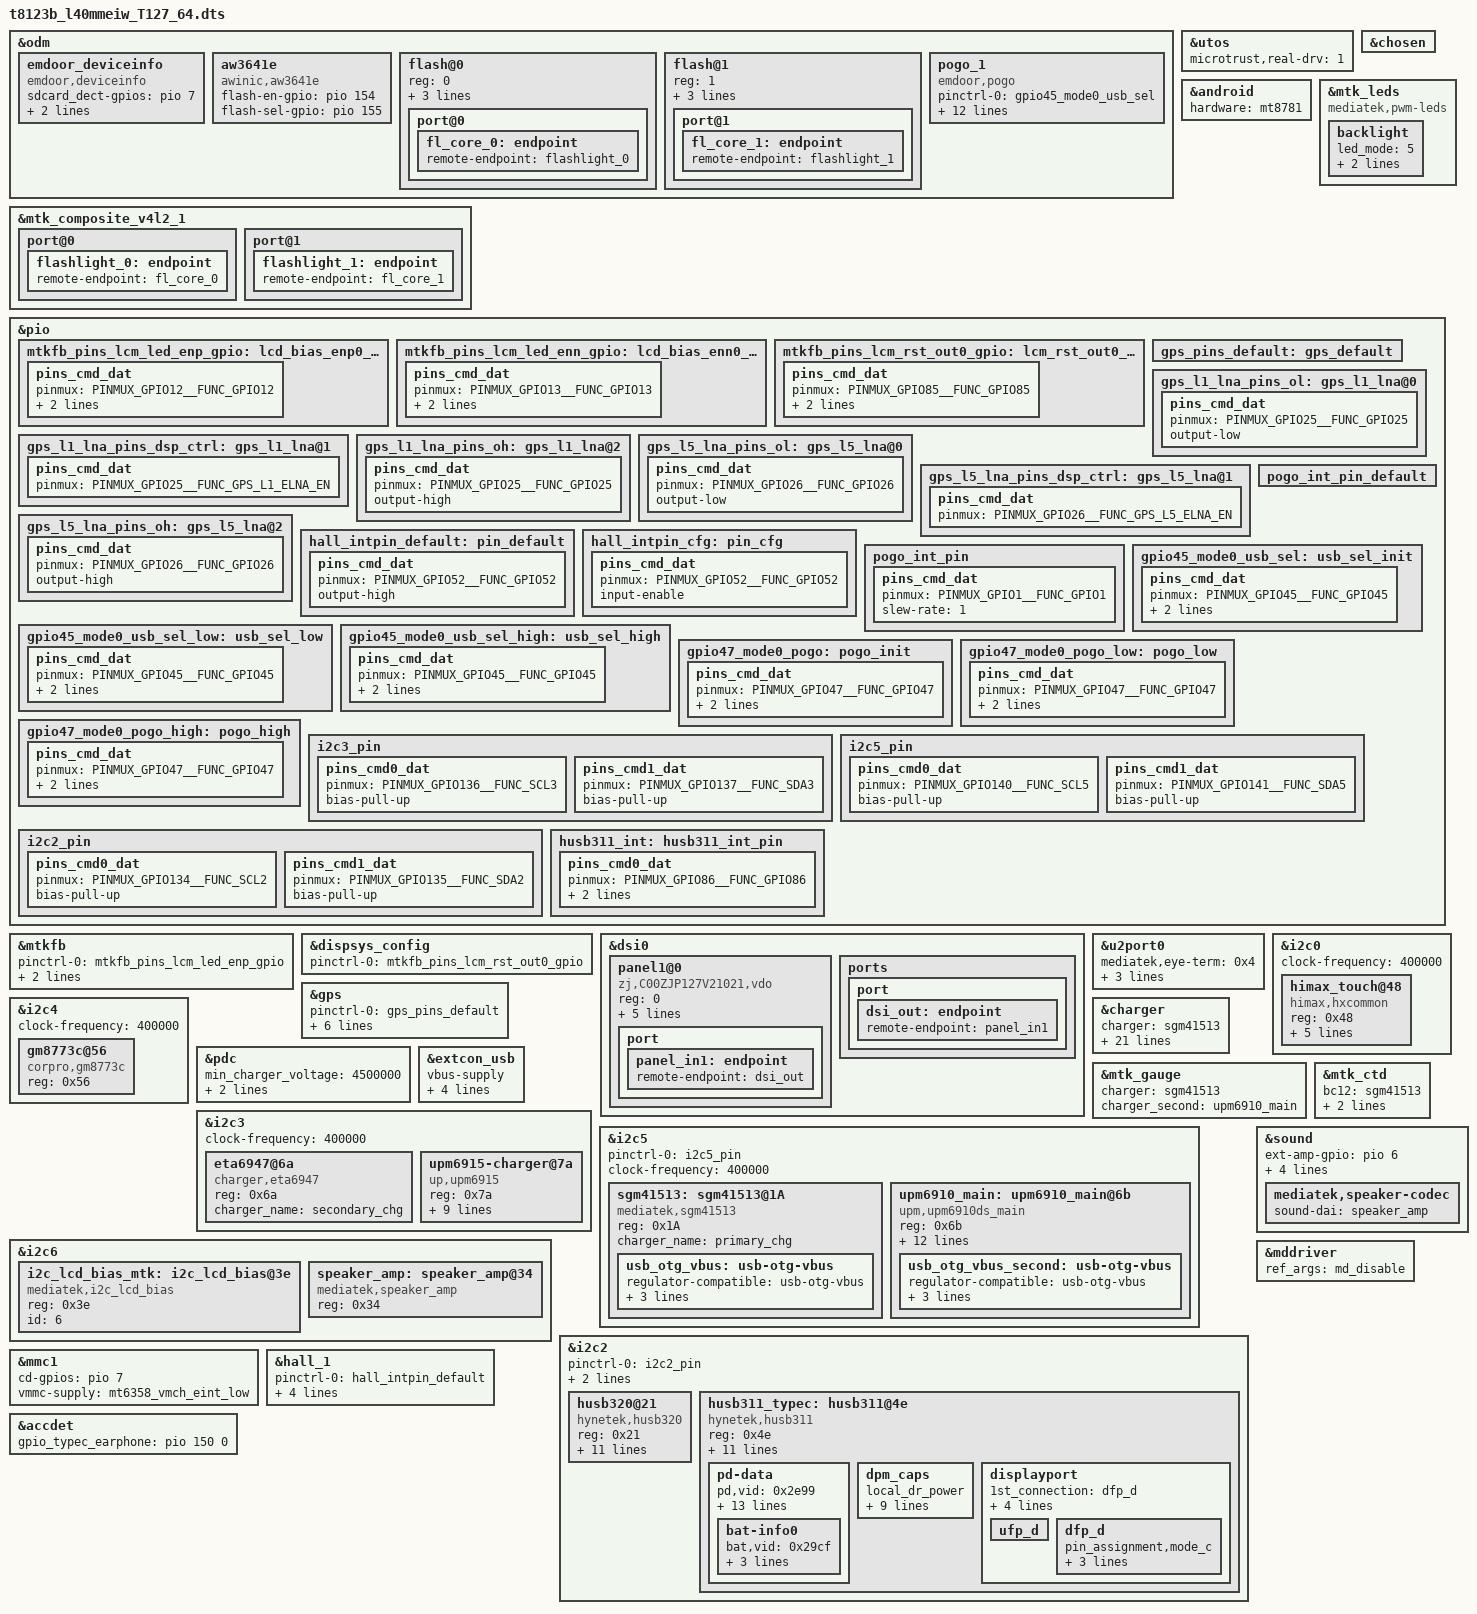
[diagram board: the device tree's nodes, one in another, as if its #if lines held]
// SPDX-License-Identifier: (GPL-2.0 OR MIT)
/*
 * Copyright (C) 2021 MediaTek Inc.
 */
/dts-v1/;
/plugin/;
#include <dt-bindings/interrupt-controller/arm-gic.h>
#include <dt-bindings/interrupt-controller/irq.h>
#include <dt-bindings/pinctrl/mt6789-pinfunc.h>
#include <dt-bindings/gpio/gpio.h>
#include "mediatek/cust_t8123b_l40mmeiw_T1095_64_camera.dtsi"

&odm {
	emdoor_deviceinfo:emdoor_deviceinfo{
		compatible = "emdoor,deviceinfo";
		sdcard_dect-gpios = <&pio 7 0>;
		ddr-name =
			"RS2G32LX4D8BNR_53BT_CX",
			"RS1G32LV4D2BDS_53BT_CX";
		status = "okay";
	};

	/* aw3641e flash  */
	aw3641e:aw3641e {
		compatible = "awinic,aw3641e";
		flash-en-gpio = <&pio 154 0>;
		flash-sel-gpio = <&pio 155 0>;
		status = "okay";
	};
	flash@0{
		reg = <0>;
		type = <0>;
		ct = <0>;
		part = <0>;
		port@0 {
			fl_core_0: endpoint {
				remote-endpoint = <&flashlight_0>;
			};
		};
	};
	flash@1{
		reg = <1>;
		type = <0>;
		ct = <1>;
		part = <0>;
		port@1 {
			fl_core_1: endpoint {
				remote-endpoint = <&flashlight_1>;
			};
		};
	};
    pogo_1: pogo_1{
        compatible = "emdoor,pogo";
        status = "okay";
    };
};

&mtk_composite_v4l2_1 {
	port@0 {
		flashlight_0: endpoint {
			remote-endpoint = <&fl_core_0>;
		};
	};
	port@1 {
		flashlight_1: endpoint {
			remote-endpoint = <&fl_core_1>;
		};
	};
};
/* Microtrust(TEEI) utos real driver */
&utos{
       microtrust,real-drv = <1>;
};

&chosen {
};

&android {
	hardware = "mt8781";
};

&mtk_leds {
	compatible = "mediatek,pwm-leds";

	backlight {
		led_mode = <5>;
		pwms =  <&disp_pwm 0 39285>;
		pwm_config = <0 1 0 0 0>;
	};
};

&pio {
	mtkfb_pins_lcm_led_enp_gpio: lcd_bias_enp0_gpio {
		pins_cmd_dat {
			pinmux = <PINMUX_GPIO12__FUNC_GPIO12>;
			slew-rate = <1>;
			output-low;
		};
	};

	mtkfb_pins_lcm_led_enn_gpio: lcd_bias_enn0_gpio {
		pins_cmd_dat {
			pinmux = <PINMUX_GPIO13__FUNC_GPIO13>;
			slew-rate = <1>;
			output-low;
		};
	};

	mtkfb_pins_lcm_rst_out0_gpio: lcm_rst_out0_gpio {
		pins_cmd_dat {
			pinmux = <PINMUX_GPIO85__FUNC_GPIO85>;
			slew-rate = <1>;
			output-low;
		};
	};
};

&mtkfb {
	pinctrl-names = "lcd_bias_enp0_gpio", "lcd_bias_enn0_gpio", "lcm_rst_out0_gpio";
	pinctrl-0 = <&mtkfb_pins_lcm_led_enp_gpio>;
	pinctrl-1 = <&mtkfb_pins_lcm_led_enn_gpio>;
	pinctrl-2 = <&mtkfb_pins_lcm_rst_out0_gpio>;
	status = "okay";
};

&dispsys_config {
	pinctrl-names = "lcm_rst_out0_gpio";
	pinctrl-0 = <&mtkfb_pins_lcm_rst_out0_gpio>;
	status = "okay";
};

&dsi0 {
	status = "okay";
	#address-cells = <1>;
	#size-cells = <0>;
	panel1@0 {
		compatible = "zj,C00ZJP127V21021,vdo";
		reg = <0>;
		reset-gpios = <&pio 85 0>;
		vdd_en-gpios = <&pio 159 0>;
		ivdd12_en-gpios = <&pio 34 0>;
		ovdd18_en-gpios = <&pio 36 0>;
		bias-gpios = <&pio 12 0>, <&pio 13 0>;
		pinctrl-names = "default";
		port {
			panel_in1: endpoint {
				remote-endpoint = <&dsi_out>;
			};
		};
	};

	ports {
		port {
			dsi_out: endpoint {
				remote-endpoint = <&panel_in1>;
			};
		};
	};
};

&u2port0 {
		mediatek,eye-term = <0x4>;
		mediatek,eye-vrt = <0x5>;
		mediatek,rev6 = <3>;
		mediatek,discth = <0xf>;
};

/* GPS GPIO standardization start */
&pio {
	gps_pins_default: gps_default {
	};
	gps_l1_lna_pins_ol: gps_l1_lna@0 {
		pins_cmd_dat {
			pinmux = <PINMUX_GPIO25__FUNC_GPIO25>;
			output-low;
		};
	};
	gps_l1_lna_pins_dsp_ctrl: gps_l1_lna@1 {
		pins_cmd_dat {
			pinmux = <PINMUX_GPIO25__FUNC_GPS_L1_ELNA_EN>;
		};
	};
	gps_l1_lna_pins_oh: gps_l1_lna@2 {
		pins_cmd_dat {
			pinmux = <PINMUX_GPIO25__FUNC_GPIO25>;
			output-high;
		};
	};
	gps_l5_lna_pins_ol: gps_l5_lna@0 {
		pins_cmd_dat {
			pinmux = <PINMUX_GPIO26__FUNC_GPIO26>;
			output-low;
		};
	};
	gps_l5_lna_pins_dsp_ctrl: gps_l5_lna@1 {
		pins_cmd_dat {
			pinmux = <PINMUX_GPIO26__FUNC_GPS_L5_ELNA_EN>;
		};
	};
	gps_l5_lna_pins_oh: gps_l5_lna@2 {
		pins_cmd_dat {
			pinmux = <PINMUX_GPIO26__FUNC_GPIO26>;
			output-high;
		};
	};

	hall_intpin_default: pin_default {
		pins_cmd_dat {
			pinmux = <PINMUX_GPIO52__FUNC_GPIO52>;
			output-high;
		};
	};
	hall_intpin_cfg: pin_cfg {
		pins_cmd_dat {
			pinmux = <PINMUX_GPIO52__FUNC_GPIO52>;
			input-enable;
		};
	};
/**pogo start**/
    pogo_int_pin_default: pogo_int_pin_default {
    };

    pogo_int_pin: pogo_int_pin {
        pins_cmd_dat {
            pinmux = <PINMUX_GPIO1__FUNC_GPIO1>;
            slew-rate = <1>;
        };
    };

    gpio45_mode0_usb_sel: usb_sel_init {
        pins_cmd_dat {
            pinmux = <PINMUX_GPIO45__FUNC_GPIO45>;
            slew-rate = <0>;
            bias-disable;
        };
    };

    gpio45_mode0_usb_sel_low: usb_sel_low {
        pins_cmd_dat {
            pinmux = <PINMUX_GPIO45__FUNC_GPIO45>;
            slew-rate = <1>;
            output-low;
        };
    };

    gpio45_mode0_usb_sel_high: usb_sel_high {
        pins_cmd_dat {
                pinmux = <PINMUX_GPIO45__FUNC_GPIO45>;
                slew-rate = <1>;
                output-high;
        };
    };

    gpio47_mode0_pogo: pogo_init {
        pins_cmd_dat {
                pinmux = <PINMUX_GPIO47__FUNC_GPIO47>;
                slew-rate = <0>;
                bias-disable;
        };
    };

    gpio47_mode0_pogo_low: pogo_low {
        pins_cmd_dat {
                pinmux = <PINMUX_GPIO47__FUNC_GPIO47>;
                slew-rate = <1>;
                output-low;
        };
    };

    gpio47_mode0_pogo_high: pogo_high {
        pins_cmd_dat {
                pinmux = <PINMUX_GPIO47__FUNC_GPIO47>;
                slew-rate = <1>;
                output-high;
        };
    };
/**pogo end**/

	i2c3_pin: i2c3_pin {
		pins_cmd0_dat {
			pinmux = <PINMUX_GPIO136__FUNC_SCL3>;
			bias-pull-up;
		};
		pins_cmd1_dat {
			pinmux = <PINMUX_GPIO137__FUNC_SDA3>;
			bias-pull-up;
		};
	};


	i2c5_pin: i2c5_pin {
		pins_cmd0_dat {
			pinmux = <PINMUX_GPIO140__FUNC_SCL5>;
			bias-pull-up;
		};
		pins_cmd1_dat {
			pinmux = <PINMUX_GPIO141__FUNC_SDA5>;
			bias-pull-up;
		};
	};

	i2c2_pin: i2c2_pin {
		pins_cmd0_dat {
			pinmux = <PINMUX_GPIO134__FUNC_SCL2>;
			bias-pull-up;
		};
		pins_cmd1_dat {
			pinmux = <PINMUX_GPIO135__FUNC_SDA2>;
			bias-pull-up;
		};
	};

	husb311_int: husb311_int_pin {
		pins_cmd0_dat {
			pinmux = <PINMUX_GPIO86__FUNC_GPIO86>;
			bias-pull-up;
			input-enable;
		};
	};

};
&gps {
	pinctrl-names = "default",
		"gps_l1_lna_disable",
		"gps_l1_lna_dsp_ctrl",
		"gps_l1_lna_enable",
		"gps_l5_lna_disable",
		"gps_l5_lna_dsp_ctrl",
		"gps_l5_lna_enable";
	pinctrl-0 = <&gps_pins_default>;
	pinctrl-1 = <&gps_l1_lna_pins_ol>;
	pinctrl-2 = <&gps_l1_lna_pins_dsp_ctrl>;
	pinctrl-3 = <&gps_l1_lna_pins_oh>;
	pinctrl-4 = <&gps_l5_lna_pins_ol>;
	pinctrl-5 = <&gps_l5_lna_pins_dsp_ctrl>;
	pinctrl-6 = <&gps_l5_lna_pins_oh>;
	status = "okay";
};
/* GPS GPIO standardization end */

&i2c0 {
    status = "okay";
    clock-frequency = <400000>;
    himax_touch@48 {
        compatible = "himax,hxcommon";
        reg = <0x48>;
        interrupt-parent = <&pio>;
        himax,panel-coords= <0 1600 0 2176>;
        himax,display-coords= <0 1600 0 2176>;
        himax,irq-gpio = <&pio 9 0x2008>;
        himax,rst-gpio = <&pio 152 0x00>;
        status = "okay" ;
    };
};

&i2c4 {
    status = "okay";
    clock-frequency = <400000>;
    gm8773c@56 {
        compatible = "corpro,gm8773c";
        reg = <0x56>;
        status = "okay";
    };
};

&charger {
	charger = <&sgm41513>;
	charger_second = <&upm6910_main>;
	battery_cv_zl = <4400000>;
	battery_cv_ytl = <4350000>;
	/* charging current */
	usb_charger_current = <500000>;
	ac_charger_current = <3000000>;
	ac_charger_input_current = <2000000>;

	chg1_ac_charger_current = <3000000>;
	chg1_ac_charger_input_current = <1100000>;

	chg2_ac_charger_current = <3000000>;
	chg2_ac_charger_input_current = <1000000>;

	charging_host_charger_current = <1500000>;

	max_charger_voltage = <12000000>;
	min_charge_temp = <0>;
	min_charge_temp_plus_x_degree = <2>;
	max_charge_temp = <45>;
	max_charge_temp_minus_x_degree = <42>;
	charger_configuration= <1>;
	/* dynamic mivr */
	enable_dynamic_mivr;
	min_charger_voltage_1 = <4600000>;
	min_charger_voltage_2 = <4600000>;
	max_dmivr_charger_current = <1800000>;
};

&pdc {
		min_charger_voltage = <4500000>;
		pd_vbus_low_bound = <5000000>;
		pd_vbus_upper_bound = <9000000>;
};

&mtk_gauge {
	charger = <&sgm41513>;
	charger_second = <&upm6910_main>;
};

&extcon_usb {
	status= "okay";
	vbus-supply;
	vbus-voltage;
	vbus-current;
	charger = <&sgm41513>;
	charger_second = <&upm6910_main>;
};

&mtk_ctd {
	bc12 = <&sgm41513>;
	bc12_second = <&upm6910_main>;
	bc12_sel = <0>;
};

&i2c3 {
	status = "okay";
	clock-frequency = <400000>;
	eta6947@6a {
		compatible = "charger,eta6947";
		reg = <0x6a>;
		charger_name = "secondary_chg";
	};
	upm6915-charger@7a {
		compatible = "up,upm6915";
		reg = <0x7a>;/*real is 0x6a*/
		up,cd-gpio = <&pio 44 0>;
		// up,otg-gpio = <&pio 3 GPIO_ACTIVE_HIGH>;
		charger_name = "secondary_chg";

		up,upm6915,usb-vindpm = <4700>;
		up,upm6915,usb-vreg = <4400>;
		up,upm6915,weak-vbat = <3400>;
		up,upm6915,termination-current = <180>;
		up,upm6915,boost-current = <1200>;
		up,upm6915,vac-ovp-threshold = <14000>;
		up,upm6915,auto-reset-32sec;
	};	
};

&i2c5 {
	status = "okay";
	pinctrl-names = "default";
	pinctrl-0 = <&i2c5_pin>;
	
	clock-frequency = <400000>;
	sgm41513: sgm41513@1A {
		status = "okay";
		compatible = "mediatek,sgm41513";
		reg = <0x1A>;
		charger_name = "primary_chg";
		//interrupt-parent = <&pio>;
		//interrupts = <4 IRQ_TYPE_EDGE_FALLING>;
		//interrupt-names = "chr_stat";

		usb_otg_vbus: usb-otg-vbus {
			regulator-compatible = "usb-otg-vbus";
			regulator-name = "usb-otg-vbus";
			regulator-min-microvolt = <5000000>;
			regulator-max-microvolt = <5000000>;
		};
	};
	
	upm6910_main: upm6910_main@6b {
		compatible = "upm,upm6910ds_main";
		reg = <0x6b>;
		upm6910x_main,intr_gpio = <&pio 4 IRQ_TYPE_EDGE_FALLING>;
		charger_name = "primary_chg";
		upm,upm6910,usb-vlim = <4700>;
		upm,upm6910,usb-ilim = <2000>;
		upm,upm6910,usb-vreg = <4400>;
		upm,upm6910,usb-ichg = <2000>;
		upm,upm6910,precharge-current = <180>;
		upm,upm6910,termination-current = <200>;
		upm,upm6910,boost-voltage = <5300>;
		upm,upm6910,boost-current = <500>;
		upm,upm6910,vac-ovp-threshold = <14000>;
		usb_otg_vbus_second: usb-otg-vbus {
			regulator-compatible = "usb-otg-vbus";
			regulator-name = "usb-otg-vbus";
			regulator-min-microvolt = <5000000>;
			regulator-max-microvolt = <5000000>;
		};
	};
};

&i2c6 {
	i2c_lcd_bias_mtk:i2c_lcd_bias@3e {
		compatible = "mediatek,i2c_lcd_bias";
		reg = <0x3e>;
		id = <6>;
		status = "okay";
	};

	speaker_amp: speaker_amp@34 {
		compatible = "mediatek,speaker_amp";
		#sound-dai-cells = <0>;
		reg = <0x34>;
		status = "okay";
	};
};

&i2c2 {
	pinctrl-names = "default", "default";
	pinctrl-0 = <&i2c2_pin>;
	pinctrl-1 = <&husb311_int>;

	clock-frequency = <100000>;

	husb320@21 {
	   compatible = "hynetek,husb320";
	   reg = <0x21>;
	   interrupt-parent = <&pio>;
	   interrupts = <86 0x2>;
	   husb320,int-gpio = <&pio 86 0>;
	   husb320,int-gpio_num = <86>;
	   gpio-controller;
	   husb320,init-mode = <28>;    //28 20 12         /* try sink, DRP */
	   husb320,host-current = <2>;                     /* 180uA host current */
	   husb320,drp-toggle-time =  <1>;                 /* 70ms */
	   husb320,drp-duty-time = <0>;                    /* 60 duty time */
	   husb320,autosink-threshold = <1>;               /* 3P1V */
	   husb320,cc-debounce-time = <3>;                 /* 150ms */
	   status = "okay";
    };

	husb311_typec: husb311@4e {
		compatible = "hynetek,husb311";
		reg = <0x4e>;
		status = "okay";
		
		interrupt-parent = <&pio>;
		//interrupts = <86 0x8>;
		tcpc-dual,supported_modes = <0>; /* 0: dfp/ufp, */
						 /* 1: dfp, 2: ufp */
		tcpc,name = "type_c_port0"; /* tcpc_device's name */
		tcpc,role_def = <4>; /* 0: SNK Only, 1: SRC Only, 2: DRP, */
					/* 3: Try.SRC, 4: Try.SNK */
		tcpc,rp_level = <2>; /* 0: Default, 1: 1.5, 2: 3.0 */
		tcpc,vconn_supply  = <0>;  /* 0: Never, 1: Always, */
					      /* 2: EMarkOnly, 3: StartOnly */
#if (CONFIG_MTK_GAUGE_VERSION == 30)
		tcpc,notifier_supply_num = <3>;
#else
		tcpc,notifier_supply_num = <2>;
#endif
		husb311pd,intr_gpio = <&pio 86 0x0>;
		husb311pd,intr_gpio_num = <86>;

		charger = <&sgm41513>;
		charger_second = <&upm6910_main>;


		pd-data {
			pd,vid = <0x2e99>;
			pd,pid = <0x0311>;
			pd,source-cap-ext = <0x171129cf 0x00000000 0x00000000
					     0x00000000 0x00000000 0x02000000>;
			pd,mfrs = "HynetekTCPC";

			/*
			 *	VSAFE5V = 0, MAX_POWER = 1, CUSTOM = 2,
			 *	MAX_POWER_LV = 0x21, MAX_POWER_LVIC = 0x31
			 *	MAX_POWER_HV = 0x41, MAX_POWER_HVIC = 0x51
			 */
			pd,charging_policy = <0x31>;

			/*
			 * Fixed 5V, 500 mA <0x00019032>
			 * Fixed 5V, 1A <0x00019064>
			 * Fixed 5V, 2A <0x000190c8>
			 * Fixed 5V, 3A <0x0001912c>
			 * Fixed 9V, 500 mA <0x0002d032>
			 * Fixed 9V, 1A <0x0002d064>
			 * Fixed 9V, 2A <0x0002d0c8>
			 * Fixed 9V, 3A <0x0002d12c>
			 * Fixed 12V,2A <0x0003c0c8>
			 * Variable 5-9V, 1A <0x8642d064>
			 * Variable 5-9V, 2A <0x8642d0c8>
			 * Variable 5-9V, 3A <0x8642d12c>
			 * PPS 3V~5.9V, 3A <0xC0761E3C>
			 */
			pd,source-pdo-size = <1>;
			pd,source-pdo-data = <0x00019032>;
			pd,sink-pdo-size = <1>;
			pd,sink-pdo-data = <0x0002d0c8>;

			/*
			 * No DP, host + device
			 *	pd,id-vdo-size = <3>;
			 *	pd,id-vdo-data = <0xd10029cf 0x0 0x17110000>;
			 * With DP
			 *	pd,id-vdo-size = <3>;
			 *	pd,id-vdo-data = <0xd60029cf 0x0 0x17110000
			 */

			pd,id-vdo-size = <3>;
			pd,id-vdo-data = <0xd10029cf 0x0 0x17110000>;

			bat,nr = <1>;
			pd,country_nr = <0>;

			bat-info0 {
				bat,vid = <0x29cf>;
				bat,pid = <0x1711>;
				bat,mfrs = "bat1";
				bat,design_cap = <3000>;
			};

			//bat-info1 {
			//	bat,vid = <0x8abc>;
			//	bat,pid = <0x5234>;
			//	bat,mfrs = "bat2";
			//	bat,design_cap = <4000>;
			//};

			//country0 {
			//	pd,country_code = <0x5457>;
			//	pd,country_len = <2>; /* max len = 26 */
			//	pd,country_data = <0xff 0xff>;
			//};

			//country1 {
			//	pd,country_code = <0x5553>;
			//	pd,country_len = <3>; /* max len = 26 */
			//	pd,country_data = <0xf1 0xf2 0xf3>;
			//};
		};
		dpm_caps {
			local_dr_power;
			local_dr_data;
			//local_ext_power;
			local_usb_comm;
			//local_usb_suspend;
			//local_high_cap;
			//local_give_back;
			local_no_suspend;
			local_vconn_supply;

			//attemp_discover_cable_dfp;
			attemp_enter_dp_mode;
			attemp_discover_cable;
			attemp_discover_id;

			/* 0: disable, 1: prefer_snk, 2: prefer_src */
			pr_check = <0>;
			//pr_reject_as_source;
			//pr_reject_as_sink;
			//pr_check_gp_source;
			//pr_check_gp_sink;

			/* 0: disable, 1: prefer_ufp, 2: prefer_dfp */
			dr_check = <0>;
			//dr_reject_as_dfp;
			//dr_reject_as_ufp;
		};
		displayport {
			/* connection type = "both", "ufp_d", "dfp_d" */
			1st_connection = "dfp_d";
			2nd_connection = "dfp_d";
			signal,dp_v13;
			//signal,dp_gen2;
			usbr20_not_used;
			typec,receptacle;
			ufp_d {
				//pin_assignment,mode_a;
				//pin_assignment,mode_b;
				//pin_assignment,mode_c;
				//pin_assignment,mode_d;
				//pin_assignment,mode_e;
			};
			dfp_d {
				/* Only support mode C & D */
				//pin_assignment,mode_a;
				//pin_assignment,mode_b;
				pin_assignment,mode_c;
				pin_assignment,mode_d;
				pin_assignment,mode_e;
				pin_assignment,mode_f;
			};
		};
	};
};


&sound {
	//mediatek,spk-i2s = <3 0>;
	ext-amp-gpio = <&pio 6 0>;
	ext-amp-gpio-one = <&pio 67 0>;
	ext-amp-gpio-three = <&pio 106 0>;
	ext-amp-gpio-four = <&pio 107 0>;	
	pa_mode = <2>;
	mediatek,speaker-codec {
		sound-dai = <&speaker_amp>;
	};
};

&mmc1 {
	cd-gpios = <&pio 7 GPIO_ACTIVE_HIGH>;
	vmmc-supply = <&mt6358_vmch_eint_low>;
};

&hall_1 {
	status = "okay";

	pinctrl-names = "pin_default", "pin_cfg";
	pinctrl-0 = <&hall_intpin_default>;
	pinctrl-1 = <&hall_intpin_cfg>;

	interrupt-parent = <&pio>;
	interrupts = <52 IRQ_TYPE_LEVEL_LOW 52 0>;
	gpio_det_level_hall_pin1 = <&pio 52 0>;
};

// pogo
&pogo_1 {
    compatible = "emdoor,pogo";

    /* usb hub */
    pinctrl-names = "usb_sel_init", "usb_sel_low", "usb_sel_high", "pogo_init", "pogo_low", "pogo_high","pogo_det_default", "pogo_det_pin";
    pinctrl-0 = <&gpio45_mode0_usb_sel>;
    pinctrl-1 = <&gpio45_mode0_usb_sel_low>;
    pinctrl-2 = <&gpio45_mode0_usb_sel_high>;
    pinctrl-3 = <&gpio47_mode0_pogo>;
    pinctrl-4 = <&gpio47_mode0_pogo_low>;
    pinctrl-5 = <&gpio47_mode0_pogo_high>;
    pinctrl-6 = <&pogo_int_pin_default>;
    pinctrl-7 = <&pogo_int_pin>;

    usb_gpio = <&pio 45 0>;
    pogo_gpio = <&pio 47 0>;
    interrupt-parent = <&pio>;
    interrupts = <1 IRQ_TYPE_LEVEL_LOW 1 0>;
    gpio_det_pogo_pin1 = <&pio 1 0>;

    status="okay";
};

&accdet {
	gpio_typec_earphone = <&pio 150 0>;
	status = "okay";
};

&mddriver {
    ref_args = "md_disable";
};

#include "mediatek/bat_setting/t8123b_CN0402R103B3435FT_8000mAh.dtsi" //中锂
#include "mediatek/bat_setting/t8123b_U299593PV_8000mAh.dtsi" //优特利

#include <t8123b_l40mmeiw_T127_64/cust.dtsi>
/*End of this file, DO NOT ADD ANYTHING HERE*/
